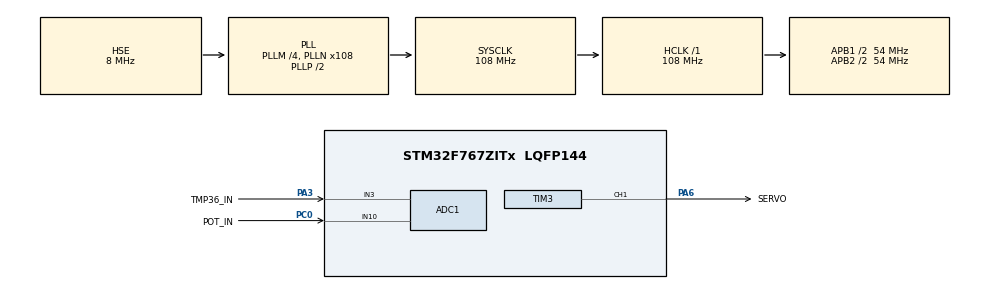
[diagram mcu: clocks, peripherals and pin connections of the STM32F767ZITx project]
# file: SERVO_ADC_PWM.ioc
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ADC1.Channel-1\#ChannelRegularConversion=ADC_CHANNEL_3
ADC1.Channel-2\#ChannelRegularConversion=ADC_CHANNEL_10
ADC1.InjNumberOfConversion=0
ADC1.NbrOfConversion=2
ADC1.NbrOfConversionFlag=1
ADC1.Rank-1\#ChannelRegularConversion=1
ADC1.Rank-2\#ChannelRegularConversion=2
ADC1.SamplingTime-1\#ChannelRegularConversion=ADC_SAMPLETIME_480CYCLES
ADC1.SamplingTime-2\#ChannelRegularConversion=ADC_SAMPLETIME_480CYCLES
ADC1.ScanConvMode=ADC_SCAN_ENABLE
ADC1.master=1
Mcu.Family=STM32F7
Mcu.Name=STM32F767ZITx
Mcu.Package=LQFP144
NVIC.PriorityGroup=NVIC_PRIORITYGROUP_4
PA3.GPIO_Label=TMP36_IN
PA3.Signal=ADCx_IN3
PA6.GPIO_Label=SERVO
PA6.Signal=S_TIM3_CH1
PC0.GPIO_Label=POT_IN
PC0.Signal=ADCx_IN10
PH0/OSC_IN.Mode=HSE-External-Oscillator
PH0/OSC_IN.Signal=RCC_OSC_IN
PH1/OSC_OUT.Mode=HSE-External-Oscillator
PH1/OSC_OUT.Signal=RCC_OSC_OUT
ProjectManager.HeapSize=0x200
ProjectManager.StackSize=0x400
ProjectManager.TargetToolchain=STM32CubeIDE
RCC.AHBFreq_Value=108000000
RCC.APB1CLKDivider=RCC_HCLK_DIV2
RCC.APB1Freq_Value=54000000
RCC.APB1TimFreq_Value=108000000
RCC.APB2CLKDivider=RCC_HCLK_DIV2
RCC.APB2Freq_Value=54000000
RCC.APB2TimFreq_Value=108000000
RCC.CortexFreq_Value=108000000
RCC.HCLKFreq_Value=108000000
RCC.HSE_VALUE=8000000
RCC.HSI_VALUE=16000000
RCC.LSE_VALUE=32768
RCC.PLLM=4
RCC.PLLN=108
RCC.PLLSourceVirtual=RCC_PLLSOURCE_HSE
RCC.SYSCLKFreq_VALUE=108000000
RCC.SYSCLKSource=RCC_SYSCLKSOURCE_PLLCLK
RCC.USBFreq_Value=108000000
RCC.VCOOutputFreq_Value=216000000
SH.ADCx_IN10.0=ADC1_IN10,IN10
SH.ADCx_IN3.0=ADC1_IN3,IN3
SH.S_TIM3_CH1.0=TIM3_CH1,PWM Generation1 CH1
TIM3.Channel-PWM\ Generation1\ CH1=TIM_CHANNEL_1
TIM3.Period=1999
TIM3.Prescaler=1079
board=custom

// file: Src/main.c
/* USER CODE BEGIN Header */
/**
  ******************************************************************************
  * @file           : main.c
  * @brief          : Main program body
  ******************************************************************************
  * @attention
  *
  * Copyright (c) 2025 STMicroelectronics.
  * All rights reserved.
  *
  * This software is licensed under terms that can be found in the LICENSE file
  * in the root directory of this software component.
  * If no LICENSE file comes with this software, it is provided AS-IS.
  *
  ******************************************************************************
  */
/* USER CODE END Header */
#include "main.h"
#include <math.f>

ADC_HandleTypeDef hadc1;
TIM_HandleTypeDef htim3;

/* USER CODE BEGIN PV */
static float currentDuty = 1.5f;
static float potFilt = 2048.0f;
/* USER CODE END PV */

void SystemClock_Config(void);
static void MX_GPIO_Init(void);
static void MX_ADC1_Init(void);
static void MX_TIM3_Init(void);

int main(void)
{

  /* MCU Configuration--------------------------------------------------------*/

  /* Reset of all peripherals, Initializes the Flash interface and the Systick. */
  HAL_Init();

  /* Configure the system clock */
  SystemClock_Config();

  /* Initialize all configured peripherals */
  MX_GPIO_Init();
  MX_ADC1_Init();
  MX_TIM3_Init();
  /* USER CODE BEGIN 2 */
  HAL_TIM_PWM_Start(&htim3, TIM_CHANNEL_1);
  /* USER CODE END 2 */

  /* Infinite loop */
  while (1)
  {

    /* USER CODE BEGIN 3 */
    uint32_t tempRaw, potRaw;

    HAL_ADC_Start(&hadc1);
    HAL_ADC_PollForConversion(&hadc1, HAL_MAX_DELAY);
    tempRaw = HAL_ADC_GetValue(&hadc1);

    HAL_ADC_PollForConversion(&hadc1, HAL_MAX_DELAY);
    potRaw = HAL_ADC_GetValue(&hadc1);

    float v = (3.3f * tempRaw) / 4095.0f;
    float tC = (v - 0.5f) * 100.0f;

    if (tC < 25.0f) tC = 25.0f;
    if (tC > 30.0f) tC = 30.0f;
    float tempNorm = (tC - 25.0f) / 5.0f;

    potFilt = 0.80f * potFilt + 0.20f * (float)potRaw;

    float targetDuty = 1.0f + (potFilt / 4095.0f) * 1.0f;

    float error = targetDuty - currentDuty;

    float base = 0.002f;
    float tempGain = 0.20f * powf(tempNorm, 2.0f);
    float errGain  = 0.50f * fabsf(error);
    float speed = base + tempGain + errGain;

    if (speed > 0.25f)  speed = 0.25f;
    if (speed < 0.002f) speed = 0.002f;

    float step = speed;
    if (step > fabsf(error)) step = fabsf(error);
    currentDuty += (error >= 0.0f ? step : -step);

    if (currentDuty < 1.0f) currentDuty = 1.0f;
    if (currentDuty > 2.0f) currentDuty = 2.0f;

    uint32_t ccr = (uint32_t)(currentDuty * 100.0f);
    __HAL_TIM_SET_COMPARE(&htim3, TIM_CHANNEL_1, ccr);

    HAL_Delay(8);
  }
  /* USER CODE END 3 */
}

void SystemClock_Config(void)
{
  RCC_OscInitTypeDef RCC_OscInitStruct = {0};
  RCC_ClkInitTypeDef RCC_ClkInitStruct = {0};

  /** Configure the main internal regulator output voltage
  */
  __HAL_RCC_PWR_CLK_ENABLE();
  __HAL_PWR_VOLTAGESCALING_CONFIG(PWR_REGULATOR_VOLTAGE_SCALE3);

  /** Initializes the RCC Oscillators according to the specified parameters
  * in the RCC_OscInitTypeDef structure.
  */
  RCC_OscInitStruct.OscillatorType = RCC_OSCILLATORTYPE_HSE;
  RCC_OscInitStruct.HSEState = RCC_HSE_ON;
  RCC_OscInitStruct.PLL.PLLState = RCC_PLL_ON;
  RCC_OscInitStruct.PLL.PLLSource = RCC_PLLSOURCE_HSE;
  RCC_OscInitStruct.PLL.PLLM = 4;
  RCC_OscInitStruct.PLL.PLLN = 108;
  RCC_OscInitStruct.PLL.PLLP = RCC_PLLP_DIV2;
  RCC_OscInitStruct.PLL.PLLQ = 2;
  RCC_OscInitStruct.PLL.PLLR = 2;
  if (HAL_RCC_OscConfig(&RCC_OscInitStruct) != HAL_OK)
  {
    Error_Handler();
  }

  /** Activate the Over-Drive mode
  */
  if (HAL_PWREx_EnableOverDrive() != HAL_OK)
  {
    Error_Handler();
  }

  /** Initializes the CPU, AHB and APB buses clocks
  */
  RCC_ClkInitStruct.ClockType = RCC_CLOCKTYPE_HCLK|RCC_CLOCKTYPE_SYSCLK
                              |RCC_CLOCKTYPE_PCLK1|RCC_CLOCKTYPE_PCLK2;
  RCC_ClkInitStruct.SYSCLKSource = RCC_SYSCLKSOURCE_PLLCLK;
  RCC_ClkInitStruct.AHBCLKDivider = RCC_SYSCLK_DIV1;
  RCC_ClkInitStruct.APB1CLKDivider = RCC_HCLK_DIV2;
  RCC_ClkInitStruct.APB2CLKDivider = RCC_HCLK_DIV2;

  if (HAL_RCC_ClockConfig(&RCC_ClkInitStruct, FLASH_LATENCY_3) != HAL_OK)
  {
    Error_Handler();
  }
}

static void MX_ADC1_Init(void)
{

  ADC_ChannelConfTypeDef sConfig = {0};

  /** Configure the global features of the ADC (Clock, Resolution, Data Alignment and number of conversion)
  */
  hadc1.Instance = ADC1;
  hadc1.Init.ClockPrescaler = ADC_CLOCK_SYNC_PCLK_DIV2;
  hadc1.Init.Resolution = ADC_RESOLUTION_12B;
  hadc1.Init.ScanConvMode = ADC_SCAN_ENABLE;
  hadc1.Init.ContinuousConvMode = DISABLE;
  hadc1.Init.DiscontinuousConvMode = DISABLE;
  hadc1.Init.ExternalTrigConvEdge = ADC_EXTERNALTRIGCONVEDGE_NONE;
  hadc1.Init.ExternalTrigConv = ADC_SOFTWARE_START;
  hadc1.Init.DataAlign = ADC_DATAALIGN_RIGHT;
  hadc1.Init.NbrOfConversion = 2;
  hadc1.Init.DMAContinuousRequests = DISABLE;
  hadc1.Init.EOCSelection = ADC_EOC_SINGLE_CONV;
  if (HAL_ADC_Init(&hadc1) != HAL_OK)
  {
    Error_Handler();
  }

  /** Configure for the selected ADC regular channel its corresponding rank in the sequencer and its sample time.
  */
  sConfig.Channel = ADC_CHANNEL_3; //TMP36
  sConfig.Rank = ADC_REGULAR_RANK_1;
  sConfig.SamplingTime = ADC_SAMPLETIME_480CYCLES;
  if (HAL_ADC_ConfigChannel(&hadc1, &sConfig) != HAL_OK)
  {
    Error_Handler();
  }

  /** Configure for the selected ADC regular channel its corresponding rank in the sequencer and its sample time.
  */
  sConfig.Channel = ADC_CHANNEL_10; //Pot. meter
  sConfig.Rank = ADC_REGULAR_RANK_2;
  if (HAL_ADC_ConfigChannel(&hadc1, &sConfig) != HAL_OK)
  {
    Error_Handler();
  }

}

static void MX_TIM3_Init(void)
{

  TIM_MasterConfigTypeDef sMasterConfig = {0};
  TIM_OC_InitTypeDef sConfigOC = {0};

  htim3.Instance = TIM3;
  htim3.Init.Prescaler = 1079;
  htim3.Init.CounterMode = TIM_COUNTERMODE_UP;
  htim3.Init.Period = 1999;
  htim3.Init.ClockDivision = TIM_CLOCKDIVISION_DIV1;
  htim3.Init.AutoReloadPreload = TIM_AUTORELOAD_PRELOAD_DISABLE;
  if (HAL_TIM_PWM_Init(&htim3) != HAL_OK)
  {
    Error_Handler();
  }
  sMasterConfig.MasterOutputTrigger = TIM_TRGO_RESET;
  sMasterConfig.MasterSlaveMode = TIM_MASTERSLAVEMODE_DISABLE;
  if (HAL_TIMEx_MasterConfigSynchronization(&htim3, &sMasterConfig) != HAL_OK)
  {
    Error_Handler();
  }
  sConfigOC.OCMode = TIM_OCMODE_PWM1;
  sConfigOC.Pulse = 0;
  sConfigOC.OCPolarity = TIM_OCPOLARITY_HIGH;
  sConfigOC.OCFastMode = TIM_OCFAST_DISABLE;
  if (HAL_TIM_PWM_ConfigChannel(&htim3, &sConfigOC, TIM_CHANNEL_1) != HAL_OK)
  {
    Error_Handler();
  }
  HAL_TIM_MspPostInit(&htim3);

}

static void MX_GPIO_Init(void)
{

  /* GPIO Ports Clock Enable */
  __HAL_RCC_GPIOH_CLK_ENABLE();
  __HAL_RCC_GPIOC_CLK_ENABLE();
  __HAL_RCC_GPIOA_CLK_ENABLE();

}

void Error_Handler(void)
{
  __disable_irq();
  while (1)
  {
  }
}
